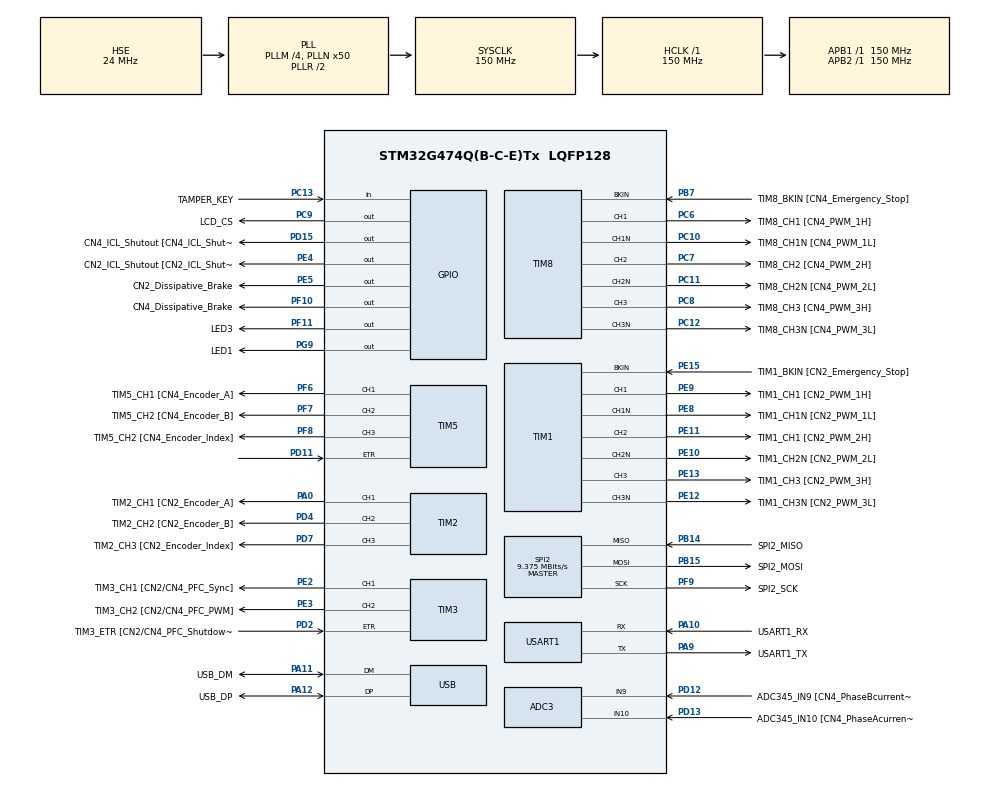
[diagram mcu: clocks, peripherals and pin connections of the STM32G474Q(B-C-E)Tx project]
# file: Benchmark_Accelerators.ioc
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ADC3.Channel-0\#ChannelRegularConversion=ADC_CHANNEL_9
ADC3.NbrOfConversionFlag=1
ADC3.OffsetNumber-0\#ChannelRegularConversion=ADC_OFFSET_NONE
ADC3.Rank-0\#ChannelRegularConversion=1
ADC3.SamplingTime-0\#ChannelRegularConversion=ADC_SAMPLETIME_2CYCLES_5
ADC3.master=1
Mcu.Family=STM32G4
Mcu.Name=STM32G474Q(B-C-E)Tx
Mcu.Package=LQFP128
NVIC.PriorityGroup=NVIC_PRIORITYGROUP_4
PA0.GPIO_Label=TIM2_CH1 [CN2_Encoder_A]
PA0.Signal=S_TIM2_CH1
PA1.Signal=OPAMP1_VINP
PA10.GPIO_Label=USART1_RX
PA10.Mode=Asynchronous
PA10.Signal=USART1_RX
PA11.GPIO_Label=USB_DM
PA11.Mode=Device
PA11.Signal=USB_DM
PA12.GPIO_Label=USB_DP
PA12.Mode=Device
PA12.Signal=USB_DP
PA13.GPIO_Label=JTMS-SWDIO
PA13.Mode=JTAG_5_pins
PA13.Signal=SYS_JTMS-SWDIO
PA14.GPIO_Label=JTCK-SWCLK
PA14.Mode=JTAG_5_pins
PA14.Signal=SYS_JTCK-SWCLK
PA15.Mode=JTAG_5_pins
PA15.Signal=SYS_JTDI
PA2.Signal=OPAMP1_VOUT
PA3.Signal=OPAMP1_VINM
PA4.Signal=COMP_DAC11_group
PA5.Signal=COMP_DAC12_group
PA6.Signal=OPAMP2_VOUT
PA7.Signal=OPAMP2_VINP
PA9.GPIO_Label=USART1_TX
PA9.Mode=Asynchronous
PA9.Signal=USART1_TX
PB0.Signal=OPAMP3_VINP
PB1.Signal=OPAMP3_VOUT
PB10.Signal=OPAMP4_VINM
PB11.Signal=OPAMP4_VINP_SEC
PB12.GPIO_Label=OPAMP4_VOUT
PB12.Signal=OPAMP4_VOUT
PB13.Signal=OPAMP4_VINP
PB14.GPIO_Label=SPI2_MISO
PB14.Mode=Full_Duplex_Master
PB14.Signal=SPI2_MISO
PB15.GPIO_Label=SPI2_MOSI
PB15.Mode=Full_Duplex_Master
PB15.Signal=SPI2_MOSI
PB2.Signal=OPAMP3_VINM
PB3.GPIO_Label=JTDO-SWO
PB3.Mode=JTAG_5_pins
PB3.Signal=SYS_JTDO-SWO
PB4.GPIO_Label=JTRST/PD_CC2
PB4.Mode=JTAG_5_pins
PB4.Signal=SYS_JTRST
PB7.GPIO_Label=TIM8_BKIN [CN4_Emergency_Stop]
PB7.Mode=Activate-Break-Input
PB7.Signal=TIM8_BKIN
PB8-BOOT0.GPIO_Label=BOOT0/FDCAN1_RX
PB8-BOOT0.Signal=FDCAN1_RX
PB9.GPIO_Label=FDCAN1_TX
PB9.Signal=FDCAN1_TX
PC0.GPIO_Label=ADC12_IN6 [CN2_PhaseCcurrent_plus]
PC0.Signal=SharedAnalog_PC0
PC1.GPIO_Label=ADC12_IN7 [CN2_Bus_Voltage]
PC1.Signal=SharedAnalog_PC1
PC10.GPIO_Label=TIM8_CH1N [CN4_PWM_1L]
PC10.Mode=Output Compare1 CH1 CH1N
PC10.Signal=TIM8_CH1N
PC11.GPIO_Label=TIM8_CH2N [CN4_PWM_2L]
PC11.Mode=Output Compare2 CH2 CH2N
PC11.Signal=TIM8_CH2N
PC12.GPIO_Label=TIM8_CH3N [CN4_PWM_3L]
PC12.Mode=Output Compare3 CH3 CH3N
PC12.Signal=TIM8_CH3N
PC13.GPIO_Label=TAMPER_KEY
PC13.Signal=GPIO_Input
PC14-OSC32_IN.GPIO_Label=PC14-OSC32_IN
PC14-OSC32_IN.Mode=LSE-External-Oscillator
PC14-OSC32_IN.Signal=RCC_OSC32_IN
PC15-OSC32_OUT.GPIO_Label=PC15-OSC32_OUT
PC15-OSC32_OUT.Mode=LSE-External-Oscillator
PC15-OSC32_OUT.Signal=RCC_OSC32_OUT
PC2.GPIO_Label=ADC12_IN8 [CN2_PhaseAcurrent_plus]
PC2.Signal=SharedAnalog_PC2
PC3.GPIO_Label=ADC12_IN9 [CN2_PhaseBcurrent_plus]
PC3.Signal=SharedAnalog_PC3
PC4.GPIO_Label=ADC2_IN5 [CN2_Heatsink_Temp]
PC4.Signal=ADC2_IN5
PC5.Signal=OPAMP2_VINM
PC6.GPIO_Label=TIM8_CH1 [CN4_PWM_1H]
PC6.Signal=S_TIM8_CH1
PC7.GPIO_Label=TIM8_CH2 [CN4_PWM_2H]
PC7.Signal=S_TIM8_CH2
PC8.GPIO_Label=TIM8_CH3 [CN4_PWM_3H]
PC8.Signal=S_TIM8_CH3
PC9.GPIO_Label=LCD_CS
PC9.Signal=GPIO_Output
PD10.GPIO_Label=ADC345_IN7 [CN4_PhaseCcurrent_plus]
PD10.Signal=SharedAnalog_PD10
PD11.Signal=S_TIM5_ETR
PD12.GPIO_Label=ADC345_IN9 [CN4_PhaseBcurrent_plus]
PD12.Signal=SharedAnalog_PD12
PD13.GPIO_Label=ADC345_IN10 [CN4_PhaseAcurrent_plus]
PD13.Signal=SharedAnalog_PD13
PD14.Signal=OPAMP2_VINP_SEC
PD15.GPIO_Label=CN4_ICL_Shutout [CN4_ICL_Shutout]
PD15.Signal=GPIO_Output
PD2.GPIO_Label=TIM3_ETR [CN2/CN4_PFC_Shutdown]
PD2.Signal=S_TIM3_ETR
PD4.GPIO_Label=TIM2_CH2 [CN2_Encoder_B]
PD4.Signal=S_TIM2_CH2
PD7.GPIO_Label=TIM2_CH3 [CN2_Encoder_Index]
PD7.Signal=S_TIM2_CH3
PD8.GPIO_Label=ADC45_IN12 [CN2/CN4_PFC_ind_current]
PD8.Signal=SharedAnalog_PD8
PD9.GPIO_Label=ADC45_IN13 [CN2_PFC_Vac]
PD9.Signal=SharedAnalog_PD9
PE10.GPIO_Label=TIM1_CH2N [CN2_PWM_2L]
PE10.Mode=Output Compare2 CH2 CH2N
PE10.Signal=TIM1_CH2N
PE11.GPIO_Label=TIM1_CH1 [CN2_PWM_2H]
PE11.Signal=S_TIM1_CH2
PE12.GPIO_Label=TIM1_CH3N [CN2_PWM_3L]
PE12.Mode=Output Compare3 CH3 CH3N
PE12.Signal=TIM1_CH3N
PE13.GPIO_Label=TIM1_CH3 [CN2_PWM_3H]
PE13.Signal=S_TIM1_CH3
PE14.GPIO_Label=ADC4_IN1 [CN4_bus_Voltage]
PE14.Signal=ADC4_IN1
PE15.GPIO_Label=TIM1_BKIN [CN2_Emergency_Stop]
PE15.Mode=Activate-Break-Input
PE15.Signal=TIM1_BKIN
PE2.GPIO_Label=TIM3_CH1 [CN2/CN4_PFC_Sync]
PE2.Signal=S_TIM3_CH1
PE3.GPIO_Label=TIM3_CH2 [CN2/CN4_PFC_PWM]
PE3.Signal=S_TIM3_CH2
PE4.GPIO_Label=CN2_ICL_Shutout [CN2_ICL_Shutout]
PE4.Signal=GPIO_Output
PE5.GPIO_Label=CN2_Dissipative_Brake
PE5.Signal=GPIO_Output
PE7.GPIO_Label=ADC3_IN4 [CN4_Heatsink_Temp]
PE7.Signal=ADC3_IN4
PE8.GPIO_Label=TIM1_CH1N [CN2_PWM_1L]
PE8.Mode=Output Compare1 CH1 CH1N
PE8.Signal=TIM1_CH1N
PE9.GPIO_Label=TIM1_CH1 [CN2_PWM_1H]
PE9.Signal=S_TIM1_CH1
PF0-OSC_IN.GPIO_Label=PF0-OSC_IN
PF0-OSC_IN.Mode=HSE-External-Oscillator
PF0-OSC_IN.Signal=RCC_OSC_IN
PF1-OSC_OUT.GPIO_Label=PF1-OSC_OUT
PF1-OSC_OUT.Mode=HSE-External-Oscillator
PF1-OSC_OUT.Signal=RCC_OSC_OUT
PF10.GPIO_Label=CN4_Dissipative_Brake
PF10.Signal=GPIO_Output
PF11.GPIO_Label=LED3
PF11.Signal=GPIO_Output
PF6.GPIO_Label=TIM5_CH1 [CN4_Encoder_A]
PF6.Signal=S_TIM5_CH1
PF7.GPIO_Label=TIM5_CH2 [CN4_Encoder_B]
PF7.Signal=S_TIM5_CH2
PF8.GPIO_Label=TIM5_CH2 [CN4_Encoder_Index]
PF8.Signal=S_TIM5_CH3
PF9.GPIO_Label=SPI2_SCK
PF9.Mode=Full_Duplex_Master
PF9.Signal=SPI2_SCK
PG6.GPIO_Label=I2C3_SMBA
PG6.GPIO_Pu=GPIO_PULLUP
PG6.Signal=I2C3_SMBA
PG7.GPIO_Label=I2C3_SCL
PG7.GPIO_Pu=GPIO_PULLUP
PG7.Signal=I2C3_SCL
PG8.GPIO_Label=I2C3_SDA
PG8.GPIO_Pu=GPIO_PULLUP
PG8.Signal=I2C3_SDA
PG9.GPIO_Label=LED1
PG9.Signal=GPIO_Output
ProjectManager.HeapSize=0x200
ProjectManager.StackSize=0x400
ProjectManager.TargetToolchain=STM32CubeIDE
RCC.ADC12Freq_Value=150000000
RCC.ADC345Freq_Value=150000000
RCC.AHBFreq_Value=150000000
RCC.APB1Freq_Value=150000000
RCC.APB1TimFreq_Value=150000000
RCC.APB2Freq_Value=150000000
RCC.APB2TimFreq_Value=150000000
RCC.CK48CLockSelection=RCC_USBCLKSOURCE_HSI48
RCC.CortexFreq_Value=150000000
RCC.EXTERNAL_CLOCK_VALUE=12288000
RCC.HCLKFreq_Value=150000000
RCC.HSE_VALUE=24000000
RCC.HSI48_VALUE=48000000
RCC.HSI_VALUE=16000000
RCC.PLLM=RCC_PLLM_DIV4
RCC.PLLN=50
RCC.PLLSourceVirtual=RCC_PLLSOURCE_HSE
RCC.SYSCLKFreq_VALUE=150000000
RCC.SYSCLKSource=RCC_SYSCLKSOURCE_PLLCLK
RCC.USBFreq_Value=48000000
RCC.VCOOutputFreq_Value=300000000
SH.COMP_DAC11_group.0=DAC1_OUT1
SH.COMP_DAC12_group.0=DAC1_OUT2
SH.S_TIM1_CH1.0=TIM1_CH1,Output Compare1 CH1 CH1N
SH.S_TIM1_CH2.0=TIM1_CH2,Output Compare2 CH2 CH2N
SH.S_TIM1_CH3.0=TIM1_CH3,Output Compare3 CH3 CH3N
SH.S_TIM2_CH1.0=TIM2_CH1,Output Compare1 CH1
SH.S_TIM2_CH2.0=TIM2_CH2,Output Compare2 CH2
SH.S_TIM2_CH3.0=TIM2_CH3,Output Compare3 CH3
SH.S_TIM3_CH1.0=TIM3_CH1,Output Compare1 CH1
SH.S_TIM3_CH2.0=TIM3_CH2,Output Compare2 CH2
SH.S_TIM3_ETR.0=TIM3_ETR,ETR-as-clearing-source
SH.S_TIM5_CH1.0=TIM5_CH1,Output Compare1 CH1
SH.S_TIM5_CH2.0=TIM5_CH2,Output Compare2 CH2
SH.S_TIM5_CH3.0=TIM5_CH3,Output Compare3 CH3
SH.S_TIM5_ETR.0=TIM5_ETR,ETR-as-clearing-source
SH.S_TIM8_CH1.0=TIM8_CH1,Output Compare1 CH1 CH1N
SH.S_TIM8_CH2.0=TIM8_CH2,Output Compare2 CH2 CH2N
SH.S_TIM8_CH3.0=TIM8_CH3,Output Compare3 CH3 CH3N
SH.SharedAnalog_PC0.0=ADC2_IN6
SH.SharedAnalog_PC0.1=ADC1_IN6
SH.SharedAnalog_PC1.0=ADC2_IN7
SH.SharedAnalog_PC1.1=ADC1_IN7
SH.SharedAnalog_PC2.0=ADC2_IN8
SH.SharedAnalog_PC2.1=ADC1_IN8
SH.SharedAnalog_PC3.0=ADC2_IN9
SH.SharedAnalog_PC3.1=ADC1_IN9
SH.SharedAnalog_PD10.0=ADC4_IN7
SH.SharedAnalog_PD10.1=ADC5_IN7
SH.SharedAnalog_PD10.2=ADC3_IN7
SH.SharedAnalog_PD12.0=ADC4_IN9
SH.SharedAnalog_PD12.1=ADC5_IN9
SH.SharedAnalog_PD12.2=ADC3_IN9,IN9-Single-Ended
SH.SharedAnalog_PD13.0=ADC4_IN10
SH.SharedAnalog_PD13.1=ADC5_IN10
SH.SharedAnalog_PD13.2=ADC3_IN10,IN10-Single-Ended
SH.SharedAnalog_PD8.0=ADC5_IN12
SH.SharedAnalog_PD8.1=ADC4_IN12
SH.SharedAnalog_PD9.0=ADC5_IN13
SH.SharedAnalog_PD9.1=ADC4_IN13
SPI2.BaudRatePrescaler=SPI_BAUDRATEPRESCALER_16
SPI2.CalculateBaudRate=9.375 MBits/s
SPI2.Direction=SPI_DIRECTION_2LINES
SPI2.Mode=SPI_MODE_MASTER
SPI2.VirtualType=VM_MASTER
TIM1.Channel-Output\ Compare1\ CH1\ CH1N=TIM_CHANNEL_1
TIM1.Channel-Output\ Compare2\ CH2\ CH2N=TIM_CHANNEL_2
TIM1.Channel-Output\ Compare3\ CH3\ CH3N=TIM_CHANNEL_3
TIM2.Channel-Output\ Compare1\ CH1=TIM_CHANNEL_1
TIM2.Channel-Output\ Compare2\ CH2=TIM_CHANNEL_2
TIM2.Channel-Output\ Compare3\ CH3=TIM_CHANNEL_3
TIM3.Channel-Output\ Compare1\ CH1=TIM_CHANNEL_1
TIM3.Channel-Output\ Compare2\ CH2=TIM_CHANNEL_2
TIM5.Channel-Output\ Compare1\ CH1=TIM_CHANNEL_1
TIM5.Channel-Output\ Compare2\ CH2=TIM_CHANNEL_2
TIM5.Channel-Output\ Compare3\ CH3=TIM_CHANNEL_3
TIM8.Channel-Output\ Compare1\ CH1\ CH1N=TIM_CHANNEL_1
TIM8.Channel-Output\ Compare2\ CH2\ CH2N=TIM_CHANNEL_2
TIM8.Channel-Output\ Compare3\ CH3\ CH3N=TIM_CHANNEL_3
USART1.VirtualMode-Asynchronous=VM_ASYNC
USART1.WordLength=WORDLENGTH_7B
VP_FMAC_VS_FMAC.Mode=FMAC_Activate
VP_HRTIM1_VS_hrtimMasterTimerNoOutput.Mode=MasterTimer
VP_SYS_VS_DBSignals.Mode=DisableDeadBatterySignals
VP_TIM8_VS_ClockSourceINT.Mode=Internal
VP_TIM8_VS_ClockSourceITR.Mode=TriggerSource_ITR0
VP_TIM8_VS_ControllerModeTrigger.Mode=Trigger Mode
board=STM32G474E-EVAL1

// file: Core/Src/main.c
/* USER CODE BEGIN Header */
/**
  ******************************************************************************
  * @file           : main.c
  * @brief          : Main program body
  ******************************************************************************
  * @attention
  *
  * Copyright (c) 2025 STMicroelectronics.
  * All rights reserved.
  *
  * This software is licensed under terms that can be found in the LICENSE file
  * in the root directory of this software component.
  * If no LICENSE file comes with this software, it is provided AS-IS.
  *
  ******************************************************************************
  */
/* USER CODE END Header */
#include "main.h"
#include "arm_math.h"

ADC_HandleTypeDef hadc3;

FMAC_HandleTypeDef hfmac;

HRTIM_HandleTypeDef hhrtim1;

SPI_HandleTypeDef hspi2;

TIM_HandleTypeDef htim1;
TIM_HandleTypeDef htim2;
TIM_HandleTypeDef htim3;
TIM_HandleTypeDef htim5;
TIM_HandleTypeDef htim8;

UART_HandleTypeDef huart1;

PCD_HandleTypeDef hpcd_USB_FS;

void SystemClock_Config(void);
static void MX_GPIO_Init(void);
static void MX_ADC3_Init(void);
static void MX_HRTIM1_Init(void);
static void MX_SPI2_Init(void);
static void MX_TIM1_Init(void);
static void MX_TIM2_Init(void);
static void MX_TIM3_Init(void);
static void MX_TIM5_Init(void);
static void MX_TIM8_Init(void);
static void MX_USART1_UART_Init(void);
static void MX_USB_PCD_Init(void);
static void MX_FMAC_Init(void);

float32_t a[5] = {1,2,3,4,5};
float32_t b[5] = {1,2,3,4,5};
float32_t c[9];
int main(void)
{

  /* MCU Configuration--------------------------------------------------------*/

  /* Reset of all peripherals, Initializes the Flash interface and the Systick. */
  HAL_Init();

  /* Configure the system clock */
  SystemClock_Config();

  /* Initialize all configured peripherals */
  MX_GPIO_Init();
  MX_ADC3_Init();
  MX_HRTIM1_Init();
  MX_SPI2_Init();
  MX_TIM1_Init();
  MX_TIM2_Init();
  MX_TIM3_Init();
  MX_TIM5_Init();
  MX_TIM8_Init();
  MX_USART1_UART_Init();
  MX_USB_PCD_Init();
  MX_FMAC_Init();
  /* USER CODE BEGIN 2 */

  arm_conv_f32(a,5,b,5,c);

  /* USER CODE END 2 */

  /* Infinite loop */
  while (1)
  {

  }
}

void SystemClock_Config(void)
{
  RCC_OscInitTypeDef RCC_OscInitStruct = {0};
  RCC_ClkInitTypeDef RCC_ClkInitStruct = {0};

  /** Configure the main internal regulator output voltage
  */
  HAL_PWREx_ControlVoltageScaling(PWR_REGULATOR_VOLTAGE_SCALE1);

  /** Initializes the RCC Oscillators according to the specified parameters
  * in the RCC_OscInitTypeDef structure.
  */
  RCC_OscInitStruct.OscillatorType = RCC_OSCILLATORTYPE_HSI48|RCC_OSCILLATORTYPE_HSE;
  RCC_OscInitStruct.HSEState = RCC_HSE_ON;
  RCC_OscInitStruct.HSI48State = RCC_HSI48_ON;
  RCC_OscInitStruct.PLL.PLLState = RCC_PLL_ON;
  RCC_OscInitStruct.PLL.PLLSource = RCC_PLLSOURCE_HSE;
  RCC_OscInitStruct.PLL.PLLM = RCC_PLLM_DIV4;
  RCC_OscInitStruct.PLL.PLLN = 50;
  RCC_OscInitStruct.PLL.PLLP = RCC_PLLP_DIV2;
  RCC_OscInitStruct.PLL.PLLQ = RCC_PLLQ_DIV2;
  RCC_OscInitStruct.PLL.PLLR = RCC_PLLR_DIV2;
  if (HAL_RCC_OscConfig(&RCC_OscInitStruct) != HAL_OK)
  {
    Error_Handler();
  }

  /** Initializes the CPU, AHB and APB buses clocks
  */
  RCC_ClkInitStruct.ClockType = RCC_CLOCKTYPE_HCLK|RCC_CLOCKTYPE_SYSCLK
                              |RCC_CLOCKTYPE_PCLK1|RCC_CLOCKTYPE_PCLK2;
  RCC_ClkInitStruct.SYSCLKSource = RCC_SYSCLKSOURCE_PLLCLK;
  RCC_ClkInitStruct.AHBCLKDivider = RCC_SYSCLK_DIV1;
  RCC_ClkInitStruct.APB1CLKDivider = RCC_HCLK_DIV1;
  RCC_ClkInitStruct.APB2CLKDivider = RCC_HCLK_DIV1;

  if (HAL_RCC_ClockConfig(&RCC_ClkInitStruct, FLASH_LATENCY_4) != HAL_OK)
  {
    Error_Handler();
  }
}

static void MX_ADC3_Init(void)
{

  ADC_MultiModeTypeDef multimode = {0};
  ADC_ChannelConfTypeDef sConfig = {0};

  /** Common config
  */
  hadc3.Instance = ADC3;
  hadc3.Init.ClockPrescaler = ADC_CLOCK_SYNC_PCLK_DIV4;
  hadc3.Init.Resolution = ADC_RESOLUTION_12B;
  hadc3.Init.DataAlign = ADC_DATAALIGN_RIGHT;
  hadc3.Init.GainCompensation = 0;
  hadc3.Init.ScanConvMode = ADC_SCAN_DISABLE;
  hadc3.Init.EOCSelection = ADC_EOC_SINGLE_CONV;
  hadc3.Init.LowPowerAutoWait = DISABLE;
  hadc3.Init.ContinuousConvMode = DISABLE;
  hadc3.Init.NbrOfConversion = 1;
  hadc3.Init.DiscontinuousConvMode = DISABLE;
  hadc3.Init.ExternalTrigConv = ADC_SOFTWARE_START;
  hadc3.Init.ExternalTrigConvEdge = ADC_EXTERNALTRIGCONVEDGE_NONE;
  hadc3.Init.DMAContinuousRequests = DISABLE;
  hadc3.Init.Overrun = ADC_OVR_DATA_PRESERVED;
  hadc3.Init.OversamplingMode = DISABLE;
  if (HAL_ADC_Init(&hadc3) != HAL_OK)
  {
    Error_Handler();
  }

  /** Configure the ADC multi-mode
  */
  multimode.Mode = ADC_MODE_INDEPENDENT;
  if (HAL_ADCEx_MultiModeConfigChannel(&hadc3, &multimode) != HAL_OK)
  {
    Error_Handler();
  }

  /** Configure Regular Channel
  */
  sConfig.Channel = ADC_CHANNEL_9;
  sConfig.Rank = ADC_REGULAR_RANK_1;
  sConfig.SamplingTime = ADC_SAMPLETIME_2CYCLES_5;
  sConfig.SingleDiff = ADC_SINGLE_ENDED;
  sConfig.OffsetNumber = ADC_OFFSET_NONE;
  sConfig.Offset = 0;
  if (HAL_ADC_ConfigChannel(&hadc3, &sConfig) != HAL_OK)
  {
    Error_Handler();
  }

}

static void MX_FMAC_Init(void)
{

  hfmac.Instance = FMAC;
  if (HAL_FMAC_Init(&hfmac) != HAL_OK)
  {
    Error_Handler();
  }

}

static void MX_HRTIM1_Init(void)
{

  HRTIM_TimeBaseCfgTypeDef pTimeBaseCfg = {0};
  HRTIM_TimerCfgTypeDef pTimerCfg = {0};

  hhrtim1.Instance = HRTIM1;
  hhrtim1.Init.HRTIMInterruptResquests = HRTIM_IT_NONE;
  hhrtim1.Init.SyncOptions = HRTIM_SYNCOPTION_NONE;
  if (HAL_HRTIM_Init(&hhrtim1) != HAL_OK)
  {
    Error_Handler();
  }
  if (HAL_HRTIM_DLLCalibrationStart(&hhrtim1, HRTIM_CALIBRATIONRATE_3) != HAL_OK)
  {
    Error_Handler();
  }
  if (HAL_HRTIM_PollForDLLCalibration(&hhrtim1, 10) != HAL_OK)
  {
    Error_Handler();
  }
  pTimeBaseCfg.Period = 0xFFDF;
  pTimeBaseCfg.RepetitionCounter = 0x00;
  pTimeBaseCfg.PrescalerRatio = HRTIM_PRESCALERRATIO_MUL32;
  pTimeBaseCfg.Mode = HRTIM_MODE_CONTINUOUS;
  if (HAL_HRTIM_TimeBaseConfig(&hhrtim1, HRTIM_TIMERINDEX_MASTER, &pTimeBaseCfg) != HAL_OK)
  {
    Error_Handler();
  }
  pTimerCfg.InterruptRequests = HRTIM_MASTER_IT_NONE;
  pTimerCfg.DMARequests = HRTIM_MASTER_DMA_NONE;
  pTimerCfg.DMASrcAddress = 0x0000;
  pTimerCfg.DMADstAddress = 0x0000;
  pTimerCfg.DMASize = 0x1;
  pTimerCfg.HalfModeEnable = HRTIM_HALFMODE_DISABLED;
  pTimerCfg.InterleavedMode = HRTIM_INTERLEAVED_MODE_DISABLED;
  pTimerCfg.StartOnSync = HRTIM_SYNCSTART_DISABLED;
  pTimerCfg.ResetOnSync = HRTIM_SYNCRESET_DISABLED;
  pTimerCfg.DACSynchro = HRTIM_DACSYNC_NONE;
  pTimerCfg.PreloadEnable = HRTIM_PRELOAD_DISABLED;
  pTimerCfg.UpdateGating = HRTIM_UPDATEGATING_INDEPENDENT;
  pTimerCfg.BurstMode = HRTIM_TIMERBURSTMODE_MAINTAINCLOCK;
  pTimerCfg.RepetitionUpdate = HRTIM_UPDATEONREPETITION_DISABLED;
  pTimerCfg.ReSyncUpdate = HRTIM_TIMERESYNC_UPDATE_UNCONDITIONAL;

  if (HAL_HRTIM_WaveformTimerConfig(&hhrtim1, HRTIM_TIMERINDEX_MASTER, &pTimerCfg) != HAL_OK)
  {
    Error_Handler();
  }

}

static void MX_SPI2_Init(void)
{

  /* SPI2 parameter configuration*/
  hspi2.Instance = SPI2;
  hspi2.Init.Mode = SPI_MODE_MASTER;
  hspi2.Init.Direction = SPI_DIRECTION_2LINES;
  hspi2.Init.DataSize = SPI_DATASIZE_4BIT;
  hspi2.Init.CLKPolarity = SPI_POLARITY_LOW;
  hspi2.Init.CLKPhase = SPI_PHASE_1EDGE;
  hspi2.Init.NSS = SPI_NSS_SOFT;
  hspi2.Init.BaudRatePrescaler = SPI_BAUDRATEPRESCALER_16;
  hspi2.Init.FirstBit = SPI_FIRSTBIT_MSB;
  hspi2.Init.TIMode = SPI_TIMODE_DISABLE;
  hspi2.Init.CRCCalculation = SPI_CRCCALCULATION_DISABLE;
  hspi2.Init.CRCPolynomial = 7;
  hspi2.Init.CRCLength = SPI_CRC_LENGTH_DATASIZE;
  hspi2.Init.NSSPMode = SPI_NSS_PULSE_ENABLE;
  if (HAL_SPI_Init(&hspi2) != HAL_OK)
  {
    Error_Handler();
  }

}

static void MX_TIM1_Init(void)
{

  TIM_MasterConfigTypeDef sMasterConfig = {0};
  TIMEx_BreakInputConfigTypeDef sBreakInputConfig = {0};
  TIM_OC_InitTypeDef sConfigOC = {0};
  TIM_BreakDeadTimeConfigTypeDef sBreakDeadTimeConfig = {0};

  htim1.Instance = TIM1;
  htim1.Init.Prescaler = 0;
  htim1.Init.CounterMode = TIM_COUNTERMODE_UP;
  htim1.Init.Period = 65535;
  htim1.Init.ClockDivision = TIM_CLOCKDIVISION_DIV1;
  htim1.Init.RepetitionCounter = 0;
  htim1.Init.AutoReloadPreload = TIM_AUTORELOAD_PRELOAD_DISABLE;
  if (HAL_TIM_OC_Init(&htim1) != HAL_OK)
  {
    Error_Handler();
  }
  sMasterConfig.MasterOutputTrigger = TIM_TRGO_RESET;
  sMasterConfig.MasterOutputTrigger2 = TIM_TRGO2_RESET;
  sMasterConfig.MasterSlaveMode = TIM_MASTERSLAVEMODE_DISABLE;
  if (HAL_TIMEx_MasterConfigSynchronization(&htim1, &sMasterConfig) != HAL_OK)
  {
    Error_Handler();
  }
  sBreakInputConfig.Source = TIM_BREAKINPUTSOURCE_BKIN;
  sBreakInputConfig.Enable = TIM_BREAKINPUTSOURCE_ENABLE;
  sBreakInputConfig.Polarity = TIM_BREAKINPUTSOURCE_POLARITY_HIGH;
  if (HAL_TIMEx_ConfigBreakInput(&htim1, TIM_BREAKINPUT_BRK, &sBreakInputConfig) != HAL_OK)
  {
    Error_Handler();
  }
  sConfigOC.OCMode = TIM_OCMODE_TIMING;
  sConfigOC.Pulse = 0;
  sConfigOC.OCPolarity = TIM_OCPOLARITY_HIGH;
  sConfigOC.OCNPolarity = TIM_OCNPOLARITY_HIGH;
  sConfigOC.OCFastMode = TIM_OCFAST_DISABLE;
  sConfigOC.OCIdleState = TIM_OCIDLESTATE_RESET;
  sConfigOC.OCNIdleState = TIM_OCNIDLESTATE_RESET;
  if (HAL_TIM_OC_ConfigChannel(&htim1, &sConfigOC, TIM_CHANNEL_1) != HAL_OK)
  {
    Error_Handler();
  }
  if (HAL_TIM_OC_ConfigChannel(&htim1, &sConfigOC, TIM_CHANNEL_2) != HAL_OK)
  {
    Error_Handler();
  }
  if (HAL_TIM_OC_ConfigChannel(&htim1, &sConfigOC, TIM_CHANNEL_3) != HAL_OK)
  {
    Error_Handler();
  }
  sBreakDeadTimeConfig.OffStateRunMode = TIM_OSSR_DISABLE;
  sBreakDeadTimeConfig.OffStateIDLEMode = TIM_OSSI_DISABLE;
  sBreakDeadTimeConfig.LockLevel = TIM_LOCKLEVEL_OFF;
  sBreakDeadTimeConfig.DeadTime = 0;
  sBreakDeadTimeConfig.BreakState = TIM_BREAK_ENABLE;
  sBreakDeadTimeConfig.BreakPolarity = TIM_BREAKPOLARITY_HIGH;
  sBreakDeadTimeConfig.BreakFilter = 0;
  sBreakDeadTimeConfig.BreakAFMode = TIM_BREAK_AFMODE_INPUT;
  sBreakDeadTimeConfig.Break2State = TIM_BREAK2_DISABLE;
  sBreakDeadTimeConfig.Break2Polarity = TIM_BREAK2POLARITY_HIGH;
  sBreakDeadTimeConfig.Break2Filter = 0;
  sBreakDeadTimeConfig.Break2AFMode = TIM_BREAK_AFMODE_INPUT;
  sBreakDeadTimeConfig.AutomaticOutput = TIM_AUTOMATICOUTPUT_DISABLE;
  if (HAL_TIMEx_ConfigBreakDeadTime(&htim1, &sBreakDeadTimeConfig) != HAL_OK)
  {
    Error_Handler();
  }
  HAL_TIM_MspPostInit(&htim1);

}

static void MX_TIM2_Init(void)
{

  TIM_MasterConfigTypeDef sMasterConfig = {0};
  TIM_OC_InitTypeDef sConfigOC = {0};

  htim2.Instance = TIM2;
  htim2.Init.Prescaler = 0;
  htim2.Init.CounterMode = TIM_COUNTERMODE_UP;
  htim2.Init.Period = 4.294967295E9;
  htim2.Init.ClockDivision = TIM_CLOCKDIVISION_DIV1;
  htim2.Init.AutoReloadPreload = TIM_AUTORELOAD_PRELOAD_DISABLE;
  if (HAL_TIM_OC_Init(&htim2) != HAL_OK)
  {
    Error_Handler();
  }
  sMasterConfig.MasterOutputTrigger = TIM_TRGO_RESET;
  sMasterConfig.MasterSlaveMode = TIM_MASTERSLAVEMODE_DISABLE;
  if (HAL_TIMEx_MasterConfigSynchronization(&htim2, &sMasterConfig) != HAL_OK)
  {
    Error_Handler();
  }
  sConfigOC.OCMode = TIM_OCMODE_TIMING;
  sConfigOC.Pulse = 0;
  sConfigOC.OCPolarity = TIM_OCPOLARITY_HIGH;
  sConfigOC.OCFastMode = TIM_OCFAST_DISABLE;
  if (HAL_TIM_OC_ConfigChannel(&htim2, &sConfigOC, TIM_CHANNEL_1) != HAL_OK)
  {
    Error_Handler();
  }
  if (HAL_TIM_OC_ConfigChannel(&htim2, &sConfigOC, TIM_CHANNEL_2) != HAL_OK)
  {
    Error_Handler();
  }
  if (HAL_TIM_OC_ConfigChannel(&htim2, &sConfigOC, TIM_CHANNEL_3) != HAL_OK)
  {
    Error_Handler();
  }
  HAL_TIM_MspPostInit(&htim2);

}

static void MX_TIM3_Init(void)
{

  TIM_MasterConfigTypeDef sMasterConfig = {0};
  TIM_OC_InitTypeDef sConfigOC = {0};

  htim3.Instance = TIM3;
  htim3.Init.Prescaler = 0;
  htim3.Init.CounterMode = TIM_COUNTERMODE_UP;
  htim3.Init.Period = 65535;
  htim3.Init.ClockDivision = TIM_CLOCKDIVISION_DIV1;
  htim3.Init.AutoReloadPreload = TIM_AUTORELOAD_PRELOAD_DISABLE;
  if (HAL_TIM_OC_Init(&htim3) != HAL_OK)
  {
    Error_Handler();
  }
  sMasterConfig.MasterOutputTrigger = TIM_TRGO_RESET;
  sMasterConfig.MasterSlaveMode = TIM_MASTERSLAVEMODE_DISABLE;
  if (HAL_TIMEx_MasterConfigSynchronization(&htim3, &sMasterConfig) != HAL_OK)
  {
    Error_Handler();
  }
  sConfigOC.OCMode = TIM_OCMODE_TIMING;
  sConfigOC.Pulse = 0;
  sConfigOC.OCPolarity = TIM_OCPOLARITY_HIGH;
  sConfigOC.OCFastMode = TIM_OCFAST_DISABLE;
  if (HAL_TIM_OC_ConfigChannel(&htim3, &sConfigOC, TIM_CHANNEL_1) != HAL_OK)
  {
    Error_Handler();
  }
  if (HAL_TIM_OC_ConfigChannel(&htim3, &sConfigOC, TIM_CHANNEL_2) != HAL_OK)
  {
    Error_Handler();
  }
  HAL_TIM_MspPostInit(&htim3);

}

static void MX_TIM5_Init(void)
{

  TIM_MasterConfigTypeDef sMasterConfig = {0};
  TIM_OC_InitTypeDef sConfigOC = {0};

  htim5.Instance = TIM5;
  htim5.Init.Prescaler = 0;
  htim5.Init.CounterMode = TIM_COUNTERMODE_UP;
  htim5.Init.Period = 4.294967295E9;
  htim5.Init.ClockDivision = TIM_CLOCKDIVISION_DIV1;
  htim5.Init.AutoReloadPreload = TIM_AUTORELOAD_PRELOAD_DISABLE;
  if (HAL_TIM_OC_Init(&htim5) != HAL_OK)
  {
    Error_Handler();
  }
  sMasterConfig.MasterOutputTrigger = TIM_TRGO_RESET;
  sMasterConfig.MasterSlaveMode = TIM_MASTERSLAVEMODE_DISABLE;
  if (HAL_TIMEx_MasterConfigSynchronization(&htim5, &sMasterConfig) != HAL_OK)
  {
    Error_Handler();
  }
  sConfigOC.OCMode = TIM_OCMODE_TIMING;
  sConfigOC.Pulse = 0;
  sConfigOC.OCPolarity = TIM_OCPOLARITY_HIGH;
  sConfigOC.OCFastMode = TIM_OCFAST_DISABLE;
  if (HAL_TIM_OC_ConfigChannel(&htim5, &sConfigOC, TIM_CHANNEL_1) != HAL_OK)
  {
    Error_Handler();
  }
  if (HAL_TIM_OC_ConfigChannel(&htim5, &sConfigOC, TIM_CHANNEL_2) != HAL_OK)
  {
    Error_Handler();
  }
  if (HAL_TIM_OC_ConfigChannel(&htim5, &sConfigOC, TIM_CHANNEL_3) != HAL_OK)
  {
    Error_Handler();
  }
  HAL_TIM_MspPostInit(&htim5);

}

static void MX_TIM8_Init(void)
{

  TIM_ClockConfigTypeDef sClockSourceConfig = {0};
  TIM_SlaveConfigTypeDef sSlaveConfig = {0};
  TIM_MasterConfigTypeDef sMasterConfig = {0};
  TIMEx_BreakInputConfigTypeDef sBreakInputConfig = {0};
  TIM_OC_InitTypeDef sConfigOC = {0};
  TIM_BreakDeadTimeConfigTypeDef sBreakDeadTimeConfig = {0};

  htim8.Instance = TIM8;
  htim8.Init.Prescaler = 0;
  htim8.Init.CounterMode = TIM_COUNTERMODE_UP;
  htim8.Init.Period = 65535;
  htim8.Init.ClockDivision = TIM_CLOCKDIVISION_DIV1;
  htim8.Init.RepetitionCounter = 0;
  htim8.Init.AutoReloadPreload = TIM_AUTORELOAD_PRELOAD_DISABLE;
  if (HAL_TIM_Base_Init(&htim8) != HAL_OK)
  {
    Error_Handler();
  }
  sClockSourceConfig.ClockSource = TIM_CLOCKSOURCE_INTERNAL;
  if (HAL_TIM_ConfigClockSource(&htim8, &sClockSourceConfig) != HAL_OK)
  {
    Error_Handler();
  }
  if (HAL_TIM_OC_Init(&htim8) != HAL_OK)
  {
    Error_Handler();
  }
  sSlaveConfig.SlaveMode = TIM_SLAVEMODE_TRIGGER;
  sSlaveConfig.InputTrigger = TIM_TS_ITR0;
  if (HAL_TIM_SlaveConfigSynchro(&htim8, &sSlaveConfig) != HAL_OK)
  {
    Error_Handler();
  }
  sMasterConfig.MasterOutputTrigger = TIM_TRGO_RESET;
  sMasterConfig.MasterOutputTrigger2 = TIM_TRGO2_RESET;
  sMasterConfig.MasterSlaveMode = TIM_MASTERSLAVEMODE_DISABLE;
  if (HAL_TIMEx_MasterConfigSynchronization(&htim8, &sMasterConfig) != HAL_OK)
  {
    Error_Handler();
  }
  sBreakInputConfig.Source = TIM_BREAKINPUTSOURCE_BKIN;
  sBreakInputConfig.Enable = TIM_BREAKINPUTSOURCE_ENABLE;
  sBreakInputConfig.Polarity = TIM_BREAKINPUTSOURCE_POLARITY_HIGH;
  if (HAL_TIMEx_ConfigBreakInput(&htim8, TIM_BREAKINPUT_BRK, &sBreakInputConfig) != HAL_OK)
  {
    Error_Handler();
  }
  sConfigOC.OCMode = TIM_OCMODE_TIMING;
  sConfigOC.Pulse = 0;
  sConfigOC.OCPolarity = TIM_OCPOLARITY_HIGH;
  sConfigOC.OCNPolarity = TIM_OCNPOLARITY_HIGH;
  sConfigOC.OCFastMode = TIM_OCFAST_DISABLE;
  sConfigOC.OCIdleState = TIM_OCIDLESTATE_RESET;
  sConfigOC.OCNIdleState = TIM_OCNIDLESTATE_RESET;
  if (HAL_TIM_OC_ConfigChannel(&htim8, &sConfigOC, TIM_CHANNEL_1) != HAL_OK)
  {
    Error_Handler();
  }
  if (HAL_TIM_OC_ConfigChannel(&htim8, &sConfigOC, TIM_CHANNEL_2) != HAL_OK)
  {
    Error_Handler();
  }
  if (HAL_TIM_OC_ConfigChannel(&htim8, &sConfigOC, TIM_CHANNEL_3) != HAL_OK)
  {
    Error_Handler();
  }
  sBreakDeadTimeConfig.OffStateRunMode = TIM_OSSR_DISABLE;
  sBreakDeadTimeConfig.OffStateIDLEMode = TIM_OSSI_DISABLE;
  sBreakDeadTimeConfig.LockLevel = TIM_LOCKLEVEL_OFF;
  sBreakDeadTimeConfig.DeadTime = 0;
  sBreakDeadTimeConfig.BreakState = TIM_BREAK_ENABLE;
  sBreakDeadTimeConfig.BreakPolarity = TIM_BREAKPOLARITY_HIGH;
  sBreakDeadTimeConfig.BreakFilter = 0;
  sBreakDeadTimeConfig.BreakAFMode = TIM_BREAK_AFMODE_INPUT;
  sBreakDeadTimeConfig.Break2State = TIM_BREAK2_DISABLE;
  sBreakDeadTimeConfig.Break2Polarity = TIM_BREAK2POLARITY_HIGH;
  sBreakDeadTimeConfig.Break2Filter = 0;
  sBreakDeadTimeConfig.Break2AFMode = TIM_BREAK_AFMODE_INPUT;
  sBreakDeadTimeConfig.AutomaticOutput = TIM_AUTOMATICOUTPUT_DISABLE;
  if (HAL_TIMEx_ConfigBreakDeadTime(&htim8, &sBreakDeadTimeConfig) != HAL_OK)
  {
    Error_Handler();
  }
  HAL_TIM_MspPostInit(&htim8);

}

static void MX_USART1_UART_Init(void)
{

  huart1.Instance = USART1;
  huart1.Init.BaudRate = 115200;
  huart1.Init.WordLength = UART_WORDLENGTH_7B;
  huart1.Init.StopBits = UART_STOPBITS_1;
  huart1.Init.Parity = UART_PARITY_NONE;
  huart1.Init.Mode = UART_MODE_TX_RX;
  huart1.Init.HwFlowCtl = UART_HWCONTROL_NONE;
  huart1.Init.OverSampling = UART_OVERSAMPLING_16;
  huart1.Init.OneBitSampling = UART_ONE_BIT_SAMPLE_DISABLE;
  huart1.Init.ClockPrescaler = UART_PRESCALER_DIV1;
  huart1.AdvancedInit.AdvFeatureInit = UART_ADVFEATURE_NO_INIT;
  if (HAL_UART_Init(&huart1) != HAL_OK)
  {
    Error_Handler();
  }
  if (HAL_UARTEx_SetTxFifoThreshold(&huart1, UART_TXFIFO_THRESHOLD_1_8) != HAL_OK)
  {
    Error_Handler();
  }
  if (HAL_UARTEx_SetRxFifoThreshold(&huart1, UART_RXFIFO_THRESHOLD_1_8) != HAL_OK)
  {
    Error_Handler();
  }
  if (HAL_UARTEx_DisableFifoMode(&huart1) != HAL_OK)
  {
    Error_Handler();
  }

}

static void MX_USB_PCD_Init(void)
{

  hpcd_USB_FS.Instance = USB;
  hpcd_USB_FS.Init.dev_endpoints = 8;
  hpcd_USB_FS.Init.speed = PCD_SPEED_FULL;
  hpcd_USB_FS.Init.phy_itface = PCD_PHY_EMBEDDED;
  hpcd_USB_FS.Init.Sof_enable = DISABLE;
  hpcd_USB_FS.Init.low_power_enable = DISABLE;
  hpcd_USB_FS.Init.lpm_enable = DISABLE;
  hpcd_USB_FS.Init.battery_charging_enable = DISABLE;
  if (HAL_PCD_Init(&hpcd_USB_FS) != HAL_OK)
  {
    Error_Handler();
  }

}

static void MX_GPIO_Init(void)
{
  GPIO_InitTypeDef GPIO_InitStruct = {0};

  /* GPIO Ports Clock Enable */
  __HAL_RCC_GPIOE_CLK_ENABLE();
  __HAL_RCC_GPIOC_CLK_ENABLE();
  __HAL_RCC_GPIOF_CLK_ENABLE();
  __HAL_RCC_GPIOA_CLK_ENABLE();
  __HAL_RCC_GPIOB_CLK_ENABLE();
  __HAL_RCC_GPIOD_CLK_ENABLE();
  __HAL_RCC_GPIOG_CLK_ENABLE();

  /*Configure GPIO pin Output Level */
  HAL_GPIO_WritePin(GPIOE, CN2_ICL_Shutout_Pin|CN2_Dissipative_Brake_Pin, GPIO_PIN_RESET);

  /*Configure GPIO pin Output Level */
  HAL_GPIO_WritePin(GPIOF, CN4_Dissipative_Brake_Pin|LED3_Pin, GPIO_PIN_RESET);

  /*Configure GPIO pin Output Level */
  HAL_GPIO_WritePin(CN4_ICL_Shutout_GPIO_Port, CN4_ICL_Shutout_Pin, GPIO_PIN_RESET);

  /*Configure GPIO pin Output Level */
  HAL_GPIO_WritePin(LCD_CS_GPIO_Port, LCD_CS_Pin, GPIO_PIN_RESET);

  /*Configure GPIO pin Output Level */
  HAL_GPIO_WritePin(LED1_GPIO_Port, LED1_Pin, GPIO_PIN_RESET);

  /*Configure GPIO pins : CN2_ICL_Shutout_Pin CN2_Dissipative_Brake_Pin */
  GPIO_InitStruct.Pin = CN2_ICL_Shutout_Pin|CN2_Dissipative_Brake_Pin;
  GPIO_InitStruct.Mode = GPIO_MODE_OUTPUT_PP;
  GPIO_InitStruct.Pull = GPIO_NOPULL;
  GPIO_InitStruct.Speed = GPIO_SPEED_FREQ_LOW;
  HAL_GPIO_Init(GPIOE, &GPIO_InitStruct);

  /*Configure GPIO pin : TAMPER_KEY_Pin */
  GPIO_InitStruct.Pin = TAMPER_KEY_Pin;
  GPIO_InitStruct.Mode = GPIO_MODE_INPUT;
  GPIO_InitStruct.Pull = GPIO_NOPULL;
  HAL_GPIO_Init(TAMPER_KEY_GPIO_Port, &GPIO_InitStruct);

  /*Configure GPIO pins : CN4_Dissipative_Brake_Pin LED3_Pin */
  GPIO_InitStruct.Pin = CN4_Dissipative_Brake_Pin|LED3_Pin;
  GPIO_InitStruct.Mode = GPIO_MODE_OUTPUT_PP;
  GPIO_InitStruct.Pull = GPIO_NOPULL;
  GPIO_InitStruct.Speed = GPIO_SPEED_FREQ_LOW;
  HAL_GPIO_Init(GPIOF, &GPIO_InitStruct);

  /*Configure GPIO pins : ADC12_IN6_Pin ADC12_IN7_Pin ADC12_IN8_Pin ADC12_IN9_Pin
                           ADC2_IN5_Pin PC5 */
  GPIO_InitStruct.Pin = ADC12_IN6_Pin|ADC12_IN7_Pin|ADC12_IN8_Pin|ADC12_IN9_Pin
                          |ADC2_IN5_Pin|GPIO_PIN_5;
  GPIO_InitStruct.Mode = GPIO_MODE_ANALOG;
  GPIO_InitStruct.Pull = GPIO_NOPULL;
  HAL_GPIO_Init(GPIOC, &GPIO_InitStruct);

  /*Configure GPIO pins : PA1 PA2 PA3 PA4
                           PA5 PA6 PA7 */
  GPIO_InitStruct.Pin = GPIO_PIN_1|GPIO_PIN_2|GPIO_PIN_3|GPIO_PIN_4
                          |GPIO_PIN_5|GPIO_PIN_6|GPIO_PIN_7;
  GPIO_InitStruct.Mode = GPIO_MODE_ANALOG;
  GPIO_InitStruct.Pull = GPIO_NOPULL;
  HAL_GPIO_Init(GPIOA, &GPIO_InitStruct);

  /*Configure GPIO pins : PB0 PB1 PB2 PB10
                           PB11 OPAMP4_VOUT_Pin PB13 */
  GPIO_InitStruct.Pin = GPIO_PIN_0|GPIO_PIN_1|GPIO_PIN_2|GPIO_PIN_10
                          |GPIO_PIN_11|OPAMP4_VOUT_Pin|GPIO_PIN_13;
  GPIO_InitStruct.Mode = GPIO_MODE_ANALOG;
  GPIO_InitStruct.Pull = GPIO_NOPULL;
  HAL_GPIO_Init(GPIOB, &GPIO_InitStruct);

  /*Configure GPIO pin : ADC4_IN1_Pin */
  GPIO_InitStruct.Pin = ADC4_IN1_Pin;
  GPIO_InitStruct.Mode = GPIO_MODE_ANALOG;
  GPIO_InitStruct.Pull = GPIO_NOPULL;
  HAL_GPIO_Init(ADC4_IN1_GPIO_Port, &GPIO_InitStruct);

  /*Configure GPIO pins : ADC45_IN12_Pin ADC45_IN13_Pin ADC345_IN7_Pin ADC345_IN9_Pin
                           ADC345_IN10_Pin PD14 */
  GPIO_InitStruct.Pin = ADC45_IN12_Pin|ADC45_IN13_Pin|ADC345_IN7_Pin|ADC345_IN9_Pin
                          |ADC345_IN10_Pin|GPIO_PIN_14;
  GPIO_InitStruct.Mode = GPIO_MODE_ANALOG;
  GPIO_InitStruct.Pull = GPIO_NOPULL;
  HAL_GPIO_Init(GPIOD, &GPIO_InitStruct);

  /*Configure GPIO pin : CN4_ICL_Shutout_Pin */
  GPIO_InitStruct.Pin = CN4_ICL_Shutout_Pin;
  GPIO_InitStruct.Mode = GPIO_MODE_OUTPUT_PP;
  GPIO_InitStruct.Pull = GPIO_NOPULL;
  GPIO_InitStruct.Speed = GPIO_SPEED_FREQ_LOW;
  HAL_GPIO_Init(CN4_ICL_Shutout_GPIO_Port, &GPIO_InitStruct);

  /*Configure GPIO pin : LCD_CS_Pin */
  GPIO_InitStruct.Pin = LCD_CS_Pin;
  GPIO_InitStruct.Mode = GPIO_MODE_OUTPUT_PP;
  GPIO_InitStruct.Pull = GPIO_NOPULL;
  GPIO_InitStruct.Speed = GPIO_SPEED_FREQ_LOW;
  HAL_GPIO_Init(LCD_CS_GPIO_Port, &GPIO_InitStruct);

  /*Configure GPIO pins : I2C3_SMBA_Pin I2C3_SCL_Pin I2C3_SDA_Pin */
  GPIO_InitStruct.Pin = I2C3_SMBA_Pin|I2C3_SCL_Pin|I2C3_SDA_Pin;
  GPIO_InitStruct.Mode = GPIO_MODE_AF_OD;
  GPIO_InitStruct.Pull = GPIO_PULLUP;
  GPIO_InitStruct.Speed = GPIO_SPEED_FREQ_LOW;
  GPIO_InitStruct.Alternate = GPIO_AF4_I2C3;
  HAL_GPIO_Init(GPIOG, &GPIO_InitStruct);

  /*Configure GPIO pin : LED1_Pin */
  GPIO_InitStruct.Pin = LED1_Pin;
  GPIO_InitStruct.Mode = GPIO_MODE_OUTPUT_PP;
  GPIO_InitStruct.Pull = GPIO_NOPULL;
  GPIO_InitStruct.Speed = GPIO_SPEED_FREQ_LOW;
  HAL_GPIO_Init(LED1_GPIO_Port, &GPIO_InitStruct);

  /*Configure GPIO pins : BOOT0_FDCAN1_RX_Pin FDCAN1_TX_Pin */
  GPIO_InitStruct.Pin = BOOT0_FDCAN1_RX_Pin|FDCAN1_TX_Pin;
  GPIO_InitStruct.Mode = GPIO_MODE_AF_PP;
  GPIO_InitStruct.Pull = GPIO_NOPULL;
  GPIO_InitStruct.Speed = GPIO_SPEED_FREQ_LOW;
  GPIO_InitStruct.Alternate = GPIO_AF9_FDCAN1;
  HAL_GPIO_Init(GPIOB, &GPIO_InitStruct);

}

void Error_Handler(void)
{
  __disable_irq();
  while (1)
  {
  }
}
